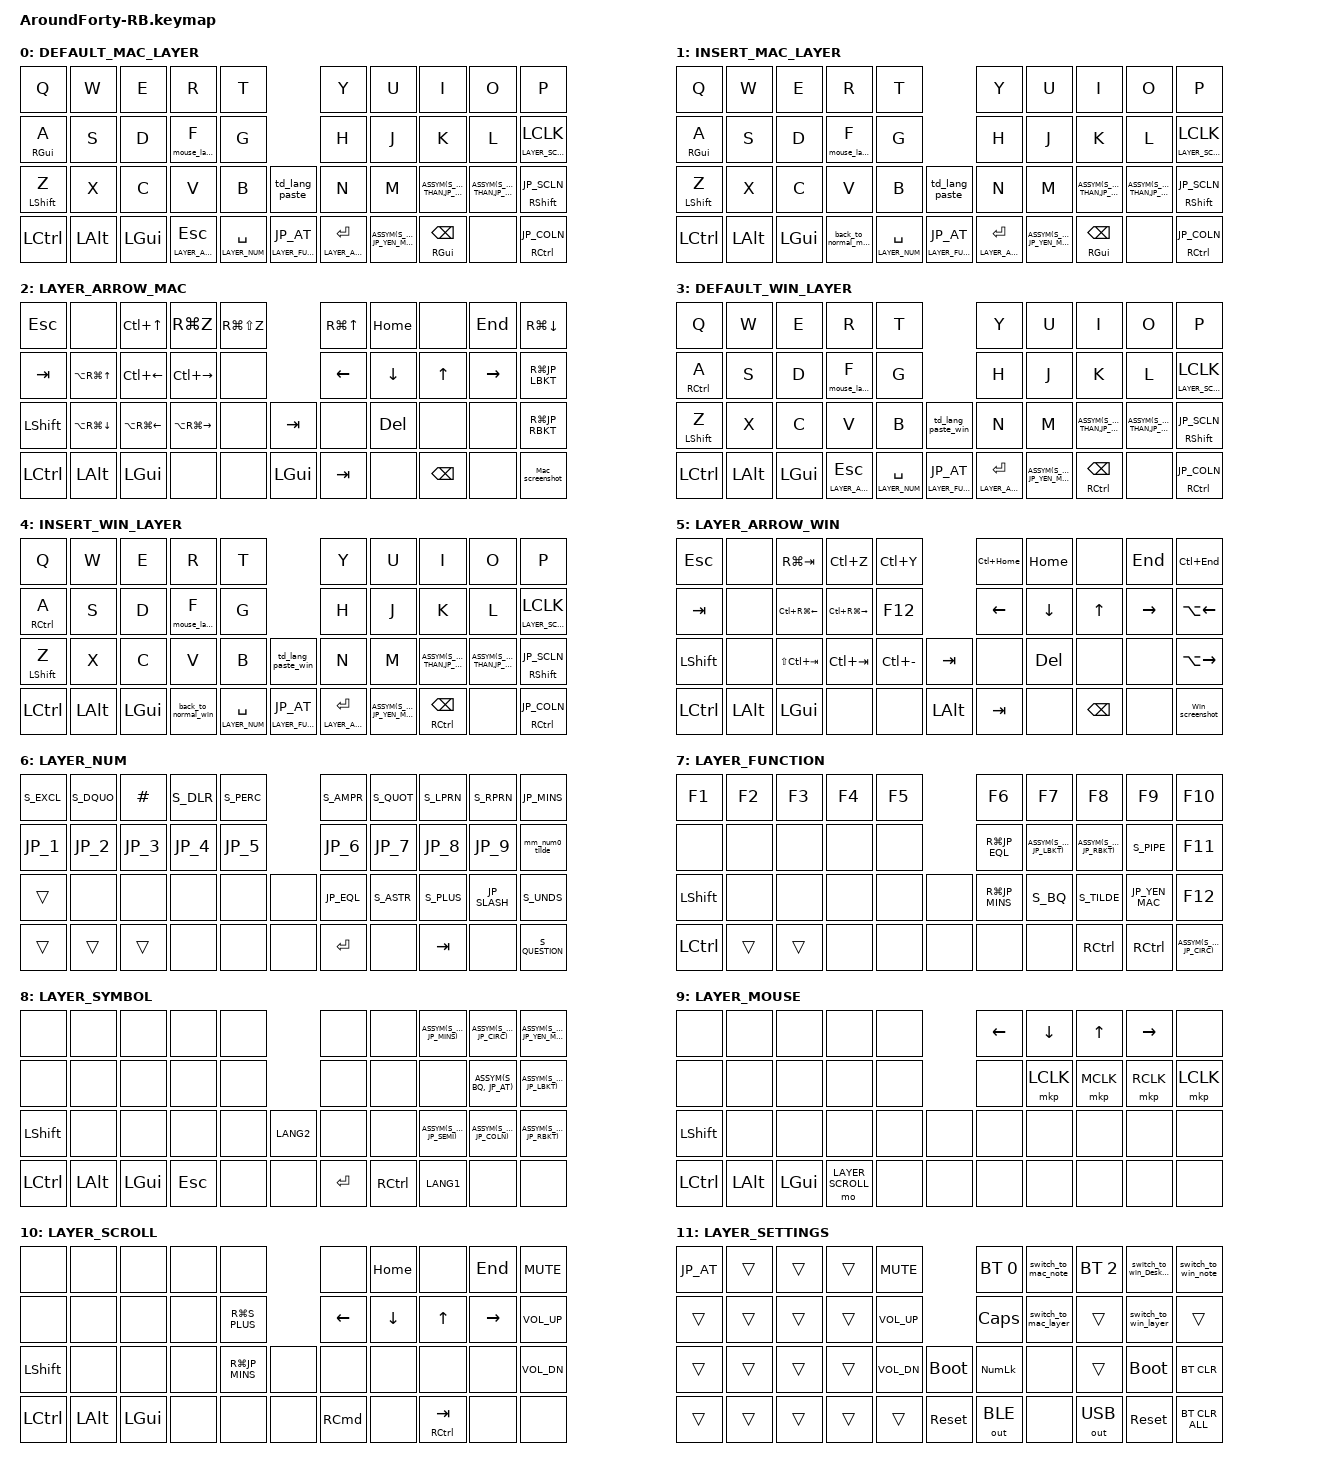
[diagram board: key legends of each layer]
#define ZMK_POINTING_DEFAULT_SCRL_VAL 120

#include <behaviors/rgbled_widget.dtsi>  // needed to use the behaviors
#include <behaviors.dtsi>
#include <dt-bindings/zmk/bt.h>
#include <dt-bindings/zmk/keys.h>
#include <dt-bindings/zmk/pointing.h>
#include <input/processors.dtsi>
#include <dt-bindings/zmk/outputs.h>

#include "code.h"

#define ASSYM(shifted, keycode) &auto_shift shifted keycode

// レイヤー定義
// デフォルトレイヤー (接続先ごと)
#define DEFAULT_MAC_LAYER      0  // Mac用デフォルトレイヤー
#define INSERT_MAC_LAYER       1  // Vim Insert(入力) Mac
#define LAYER_ARROW_MAC        2  // 矢印移動Macキーレイヤー

#define DEFAULT_WIN_LAYER      3  // Windows用デフォルトレイヤー
#define INSERT_WIN_LAYER       4  // Vim Insert(入力) Win
#define LAYER_ARROW_WIN        5  // 矢印移動Winキーレイヤー

// 機能レイヤー
#define LAYER_NUM 6            // 数字キーレイヤー
#define LAYER_FUNCTION 7       // ファンクションキーレイヤー
#define LAYER_SYMBOL 8         // 記号レイヤー
#define LAYER_MOUSE  9         // マウス操作レイヤー
#define LAYER_SCROLL 10        // スクロールレイヤー
#define LAYER_SETTINGS 11       // 設定レイヤー

//AML関連設定
//&zip_temp_layer {
//    excluded-positions = <
//        6 // U
//        7 // I
//        8 // O
//        //16 // J
//        //17 // K
//        //18 // L
//        //27 // M
//        //29 // .
//        31 // LEFT_CONTROL
//    >;
//};
//
////キー入力から一定時間はAMLを発動しない
//&zip_temp_layer {
//    require-prior-idle-ms = <500>;
//};
////マウスキーを押したらタイムアウトを延長する
//&mkp_input_listener {
//    input-processors = <&zip_temp_layer LAYER_MOUSE 10000>;
//};
////マウスキーを押すまでマウスレイヤーに留まる(マウスキーを押したらタイムアウトを延長すると同じ実装で、タイムアウト時間が違うだけ)
//&mkp_input_listener {
//    input-processors = <&zip_temp_layer LAYER_MOUSE 250>;
//};

&mt {
    flavor = "balanced";
    quick-tap-ms = <0>;
 
};

/ {
    combos {
        compatible = "zmk,combos"; 
        
        To_LayerSYMBOL {
            timeout-ms = <50>;
            bindings = <&togle_symbol>;  // SYMBOLレイヤーに移動

            key-positions = <11 12>;
            layers = <
                DEFAULT_MAC_LAYER           // Mac
                DEFAULT_WIN_LAYER           // Windows  
                LAYER_SYMBOL
            >;
        };

        To_LayerSETTING {
            bindings = <&mo LAYER_SETTINGS>;  // 設定レイヤーに移動
            //combo-term-ms = 30;
            key-positions = <34 35>;
        };

        // Mac: レイヤー戻しコンボ（ESCなし）
        combo_back_to_default_mac {
            timeout-ms = <800>;
            key-positions = <34 37>;
            bindings = <&back_to_default_mac>;
            layers = <INSERT_MAC_LAYER>, <DEFAULT_MAC_LAYER>;
        };

        // Win: レイヤー戻しコンボ（ESCなし）
        combo_back_to_default_win {
            timeout-ms = <800>;
            key-positions = <34 37>;
            bindings = <&back_to_default_win>;
            layers = <INSERT_WIN_LAYER>, <DEFAULT_WIN_LAYER>;
        };
 
        // f (13) + 右上1 (9) ➔ パイプ |
        combo_pipe { timeout-ms = <300>; key-positions = <13 9>; bindings = <&macro_pipe>; };
    
        // f (13) + 右上2 (19) ➔ 円マーク ¥
        combo_yen { timeout-ms = <300>; key-positions = <13 19>; bindings = <&macro_backslash>; };
    
        // f (13) + 右上3 (30) ➔ アンダーバー _
        combo_under { timeout-ms = <300>; key-positions = <13 30>; bindings = <&macro_under>; };

                /*
         * J + K：左クリック
         *
         * slow-releaseにより、
         * コンボ成立後にKを離しても、
         * Jを押している間は左クリックを維持する。
         */
        /* K + L：中クリック */
        combo_middle_click {
            timeout-ms = <40>;
            key-positions = <17 18>;
            bindings = <&mkp MCLK>;
            slow-release;
            //layers = <0>;
        };

        /* L + ;：右クリック */
        combo_right_click {
            timeout-ms = <40>;
            key-positions = <18 19>;
            bindings = <&mkp RCLK>;
            slow-release;
            //layers = <0>;
        };
    };

    macros {
        // F長押し時にMouse Layerを即時有効化する
        mouse_layer_eisu_hold: mouse_layer_eisu_hold {
            compatible = "zmk,behavior-macro";
            #binding-cells = <0>;
            wait-ms = <0>; tap-ms = <40>;
            bindings = <&macro_press &mo LAYER_MOUSE>, <&macro_pause_for_release>, <&macro_release &mo LAYER_MOUSE>;
        };

        // 指定したマウスボタンをクリックする
        mouse_button_eisu: mouse_button_eisu {
            compatible = "zmk,behavior-macro-one-param";
            #binding-cells = <1>;
            wait-ms = <30>; tap-ms = <40>;
            bindings = <&macro_param_1to1>, <&macro_tap &mkp MACRO_PLACEHOLDER>;
        };

        // パイプ | (Alt + 124)
        macro_pipe: macro_pipe {
            compatible = "zmk,behavior-macro";
            #binding-cells = <0>;
            wait-ms = <30>; tap-ms = <40>;
            bindings = <&macro_press &kp LALT>, <&macro_tap &kp KP_N1 &kp KP_N2 &kp KP_N4>, <&macro_release &kp LALT>;
        };
    
        // 円マーク ¥ (Alt + 165)
        macro_yen: macro_yen {
            compatible = "zmk,behavior-macro";
            #binding-cells = <0>;
            wait-ms = <30>; tap-ms = <40>;
            bindings = <&macro_press &kp LALT>, <&macro_tap &kp KP_N1 &kp KP_N6 &kp KP_N5>, <&macro_release &kp LALT>;
        };
    
        // アンダーバー _ (Alt + 95)
        macro_under: macro_under {
            compatible = "zmk,behavior-macro";
            #binding-cells = <0>;
            wait-ms = <30>; tap-ms = <40>;
            bindings = <&macro_press &kp LALT>, <&macro_tap &kp KP_N9 &kp KP_N5>, <&macro_release &kp LALT>;
        };
    
        // バックスラッシュ \ (Alt + 92)
        macro_backslash: macro_backslash {
            compatible = "zmk,behavior-macro";
            #binding-cells = <0>;
            wait-ms = <30>; tap-ms = <40>;
            bindings = <&macro_press &kp LALT>, <&macro_tap &kp KP_N9 &kp KP_N2>, <&macro_release &kp LALT>;
        };
 
        // Mac用: スロット1に合わせ、他を切断
        switch_to_mac_note: switch_to_mac_note {
            compatible = "zmk,behavior-macro";
            #binding-cells = <0>;
            bindings = <
                &macro_wait_time 50
                &bt BT_SEL 1
                &bt BT_DISC 0
                &bt BT_DISC 2
                &bt BT_DISC 3
                &bt BT_DISC 4
                &out OUT_BLE
            >;
        };

        // Win用: スロット3に合わせ、他を切断
        switch_to_win_Desktop: switch_to_win_Desktop {
            compatible = "zmk,behavior-macro";
            #binding-cells = <0>;
            bindings = <
                &macro_wait_time 50
                &bt BT_SEL 3
                &bt BT_DISC 0
                &bt BT_DISC 1
                &bt BT_DISC 2
                &bt BT_DISC 4
                &out OUT_BLE
            >;
        };

        // Win用: スロット4に合わせ、他を切断
        switch_to_win_note: switch_to_win_note {
            compatible = "zmk,behavior-macro";
            #binding-cells = <0>;
            bindings = <
                &macro_wait_time 50
                &bt BT_SEL 4
                &bt BT_DISC 0
                &bt BT_DISC 1
                &bt BT_DISC 2
                &bt BT_DISC 3
                &out OUT_BLE
            >;
        };

        // デフォルトレイヤーOFF
        reset_DefaultLayer: reset_DefaultLayer {
            compatible = "zmk,behavior-macro";
            #binding-cells = <0>;
            bindings = <

                // レイヤーをオフ
                &tog_off DEFAULT_MAC_LAYER 
                &tog_off DEFAULT_WIN_LAYER 
            >;
            label = "reset_DefaultLayer";
        };
        
        // Mac layer
        switch_to_mac_layer: switch_to_mac_layer {
            compatible = "zmk,behavior-macro";
            #binding-cells = <0>;
    
            bindings = <
                &reset_DefaultLayer
                &macro_wait_time 200

                // Bluetooth切断
                &bt BT_DISC 3
                &bt BT_DISC 4 

                &tog_on DEFAULT_MAC_LAYER
                &to DEFAULT_MAC_LAYER
                &out OUT_BLE
            >;
            label = "SWITCH_TO_MAC_LALYER";
        };

        // Win layer
        switch_to_win_layer: switch_to_win_layer {
            compatible = "zmk,behavior-macro";
            #binding-cells = <0>;
    
            bindings = <
                &reset_DefaultLayer
                &macro_wait_time 200

                // Bluetooth切断
                &bt BT_DISC 0
                &bt BT_DISC 1
                &bt BT_DISC 2

                &tog_on DEFAULT_WIN_LAYER
                &to DEFAULT_WIN_LAYER
                &out OUT_BLE
            >;
            label = "SWITCH_TO_WIN_LALYER";
        };

        to_layer_0: to_layer_0 {
            compatible = "zmk,behavior-macro-one-param";
            #binding-cells = <1>;
            bindings = <&to 0 &macro_param_1to1 &kp MACRO_PLACEHOLDER>;
            label = "TO_LAYER_0";
        };

        Mac_screenshot: Mac_screenshot {
            compatible = "zmk,behavior-macro";
            #binding-cells = <0>;
            bindings = <&kp RG(LS(N5))>;
            label = "MAC_SCREENSHOT";
        };

        Win_screenshot: Win_screenshot {
            compatible = "zmk,behavior-macro";
            #binding-cells = <0>;
            bindings = <&kp RG(LS(S))>;
            label = "WIN_SCREENSHOT";
        };

        to_default_layer: to_default_layer {
            compatible = "zmk,behavior-macro";
            #binding-cells = <0>;
            bindings = <&to DEFAULT_MAC_LAYER &to DEFAULT_WIN_LAYER>;
            label = "TO_DEFAULT_LAYER";
        };

        exit_num_lang2: exit_num_lang2 {
            compatible = "zmk,behavior-macro";
            #binding-cells = <0>;
            bindings = <
                &to_default_layer
                &kp LANG2
            >;
            label = "EXIT_NUM_LANG2";
        };

        exit_num_lang1: exit_num_lang1 {
            compatible = "zmk,behavior-macro";
            #binding-cells = <0>;
            bindings = <
                &to_default_layer
                &kp LANG1
            >;
            label = "EXIT_NUM_LANG1";
        };

        // 記号レイヤー移動
        togle_symbol: togle_symbol {
            label = "TOGGLE_SYMBOL";
            compatible = "zmk,behavior-macro";
            #binding-cells = <0>;
            bindings = 
                <&tog LAYER_SYMBOL>;  // 記号レイヤーに移動
        };

        // 入力レイヤー用：Esc→各OSのデフォルト（Vimノーマル）へ戻す（旧定義：残す）
        back_to_normal_mac: back_to_normal_mac {
            compatible = "zmk,behavior-macro";
            #binding-cells = <0>;
            bindings = <
                &kp ESCAPE          // Vimノーマルmodeへ
                &macro_wait_time 50
                &to DEFAULT_MAC_LAYER // Macデフォルトへ
            >;
        };

        back_to_normal_win: back_to_normal_win {
            compatible = "zmk,behavior-macro";
            #binding-cells = <0>;
            bindings = <
                &kp ESCAPE          // Vimノーマルmodeへ
                &macro_wait_time 50
                &to DEFAULT_WIN_LAYER // Winデフォルトへ
            >;
        };

        // ESCなしでレイヤー戻し（Mac用）- コンボ用
        back_to_default_mac: back_to_default_mac {
            compatible = "zmk,behavior-macro";
            #binding-cells = <0>;
            bindings = <
                &to DEFAULT_MAC_LAYER
            >;
        };

        // ESCなしでレイヤー戻し（Win用）- コンボ用
        back_to_default_win: back_to_default_win {
            compatible = "zmk,behavior-macro";
            #binding-cells = <0>;
            bindings = <
                &to DEFAULT_WIN_LAYER
            >;
        };

        /* --- ESCとLang2を送る --- */
        esc_lang: esc_lang {
            compatible = "zmk,behavior-macro";
            #binding-cells = <0>;
            bindings = <
                &kp ESCAPE                // Escape
                &kp LANG2                 // 半角入力へ
            >;
        };

        // Altを2回送るマクロ
        win_clip_altalt: win_clip_altalt {
            compatible = "zmk,behavior-macro";
            #binding-cells = <0>;
            bindings = <
                &kp LALT            // 1回目
                &macro_wait_time 80 // 適宜調整
                &kp LALT            // 2回目
            >;
        };
    };

    behaviors {
        lt_to_layer_0: lt_to_layer_0 {
            compatible = "zmk,behavior-hold-tap";
            label = "LAYER_TAP_TO_0";
            bindings = <&mo>, <&to_layer_0>;

            #binding-cells = <2>;
            tapping-term-ms = <200>;
        };

        scroll_up_down: behavior_sensor_rotate_mouse_wheel_up_down {
            compatible = "zmk,behavior-sensor-rotate";
            #sensor-binding-cells = <0>;
            bindings = <&msc SCRL_UP>, <&msc SCRL_DOWN>;

            tap-ms = <20>;
        };

        //AutoShift
        auto_shift: auto_shift {
            compatible = "zmk,behavior-hold-tap";
            #binding-cells = <2>;
            tapping_term_ms = <180>;
            quick_tap_ms = <200>;
            flavor = "tap-preferred";
            require-prior-idle-ms = <120>;
            bindings = <&kp>, <&kp>;
        };

        //移動レイヤートグル
        lt_arrow_tog: lt_arrow_tog {
            compatible = "zmk,behavior-hold-tap";
            label = "LAYER_ARROW_TOG";
            #binding-cells = <2>;
            tapping-term-ms = <200>;
            quick-tap-ms = <0>;
            flavor = "tap-preferred";
            bindings = <&tog>, <&kp>;
        };

        //矢印レイヤーに移動がたまに失敗するため
        lt_arrow: lt_arrow {
            compatible = "zmk,behavior-hold-tap";
            label = "LAYER_TAP_ARROW";
            #binding-cells = <2>;
            tapping-term-ms = <250>;
            quick-tap-ms = <200>;
            flavor = "hold-preferred";
            bindings = <&mo>, <&kp>;
        };

        lt_layer_tap_preferred: lt_layer_tap_preferred {
            compatible = "zmk,behavior-hold-tap";
            label = "LAYER_TAP_TAP_PREF";
            #binding-cells = <2>;
            tapping-term-ms = <200>;
            flavor = "tap-preferred";
            bindings = <&mo>, <&kp>;
        };

        /*
         * 単押しではマウスボタン、長押し中は指定したレイヤーを有効にする。
         *
         * 使い方:
         *   &lt_mkp LAYER_SCROLL LCLK
         *   1つ目: 長押し中に有効にするレイヤー
         *   2つ目: 単押しで送るマウスボタン
         */
        lt_mkp: lt_mkp {
            compatible = "zmk,behavior-hold-tap";
            label = "LAYER_TAP_MOUSE_BUTTON";
            #binding-cells = <2>;
            tapping-term-ms = <200>;
            quick-tap-ms = <0>;
            flavor = "hold-preferred";
            bindings = <&mo>, <&mouse_button_eisu>;
        };

        // F: タップはF、長押しは英数化してMouse Layerを有効にする
        lt_mouse_eisu: lt_mouse_eisu {
            compatible = "zmk,behavior-hold-tap";
            label = "LAYER_TAP_MOUSE_EISU";
            #binding-cells = <2>;
            flavor = "tap-preferred";
            tapping-term-ms = <200>;
            bindings = <&mouse_layer_eisu_hold>, <&kp>;
        };

        /* 注意:
        *  - bindings の tap 側を &kp から &td_* に差し替えるため、
        *    keymap から渡す引数は「レイヤー」だけになる
        *  - そのため #binding-cells は <1> にする
        */
        // Arrow用: hold=押している間レイヤー / tap=（1回LANG2,2回ESC）
        lt_arrow_td: lt_arrow_td {
            compatible = "zmk,behavior-hold-tap";           // #hold-tap
            label = "LAYER_TAP_ARROW_TD";                   // #識別ラベル
            #binding-cells = <2>;                           // #引数はレイヤー1つだけ
            tapping-term-ms = <250>;                        // #元の lt_arrow と同じ
            quick-tap-ms = <200>;                           // #元の lt_arrow と同じ
            flavor = "hold-preferred";                      // #元の lt_arrow と同じ
            bindings = <&mo>, <&td_lang2_esc>;              // #hold=&mo, #tap=&td_lang2_esc
        };

        // Function用: hold=押している間レイヤー / tap=&kp
        lt_layer_tap_preferred_td: lt_layer_tap_preferred_td {
            compatible = "zmk,behavior-hold-tap";           // #hold-tap
            label = "LAYER_TAP_TAP_PREF_TD";                // #識別ラベル
            #binding-cells = <2>;                           // #引数はレイヤー1つだけ
            tapping-term-ms = <200>;                        // #元の lt_layer_tap_preferred と同じ
            flavor = "tap-preferred";                       // #元の lt_layer_tap_preferred と同じ
            bindings = <&mo>, <&kp>;                        // #hold=&mo, #tap=&kp
        };
        
        tog_on: toggle_layer_on_only {
            compatible = "zmk,behavior-toggle-layer";
            #binding-cells = <1>;
            display-name = "Toggle Layer On";
            toggle-mode = "on";
        };

        tog_off: toggle_layer_off_only {
            compatible = "zmk,behavior-toggle-layer";
            #binding-cells = <1>;
            display-name = "Toggle Layer Off";
            toggle-mode = "off";
        };

        ht_kp_tap: ht_kp_tap {
            compatible = "zmk,behavior-hold-tap";
            label = "HT_KP_TAP_PREF";
            #binding-cells = <2>;
            tapping-term-ms = <200>;      // 好みで共通値
            quick-tap-ms = <200>;         // 要らなければ削除
            flavor = "tap-preferred";
            bindings = <&kp>, <&kp>;
        };

        ht_kp_hold: ht_kp_hold {
            compatible = "zmk,behavior-hold-tap";
            label = "HT_KP_HOLD_PREF";
            #binding-cells = <2>;
            tapping-term-ms = <200>;
            quick-tap-ms = <200>;
            flavor = "hold-preferred";
            bindings = <&kp>, <&kp>;
        };

        td_lang_paste: td_lang_paste {
            compatible = "zmk,behavior-tap-dance";
            label = "TD_LANG_PASTE";
            #binding-cells = <0>;
            tapping-term-ms = <350>;
            bindings = <&kp LANG2>, <&kp LANG1>, <&kp LC(LA(V))>;
        };

        // tap dance の3タップ目に差し込む
        td_lang_paste_win: td_lang_paste_win {
            compatible = "zmk,behavior-tap-dance";
            #binding-cells = <0>;
            label = "TD_LANG_PASTE_WIN";
            tapping-term-ms = <350>;
            bindings = <
                &kp INT_MUHENKAN  // 英数 (Meltype: 無変換で英数)
                &kp INT_HENKAN    // 日本語 (Meltype: 変換で日本語)
                &win_clip_altalt           
            >;
        };

        // ================================
        // ① td_lang2_esc → td_lang1_esc 置換
        //    Insertレイヤ用：1tap=日本語 / 2tap=ESC
        // ================================ */
        td_lang1_esc: td_lang1_esc {
            compatible = "zmk,behavior-tap-dance";     // 日本語寄せ＋Esc 用 tap-dance
            label = "TD_LANG1_ESC";                    // 任意ラベル（識別用）
            #binding-cells = <0>;
            tapping-term-ms = <350>;                   // 既存 td_lang2_esc と同等想定
            bindings = <&kp LANG1>, <&kp ESCAPE>;      // 1tap=LANG1 / 2tap=ESC
        };

        // 1回: LANG2 / 2回: ESCAPE（holdは lt_arrow 側で LAYER_ARROW_MAC のまま）
        td_lang2_esc: td_lang2_esc {
            compatible = "zmk,behavior-tap-dance";          // tap-dance behavior
            label = "TD_LANG2_ESC";                         // 任意ラベル（識別用）
            #binding-cells = <0>;                           // 引数なしで参照する
            tapping-term-ms = <350>;                        // 2回目受付時間（必要なら調整）
            bindings = <&kp LANG2>, <&kp ESCAPE>;           // 1回目 / 2回目
        };


        // 旧定義：残す（入力レイヤー用：1tap=LANG2 / 2tap=ESC / 3tap=back_to_normal_*）
        td_lang2_back_mac: td_lang2_back_mac {
            compatible = "zmk,behavior-tap-dance";
            #binding-cells = <0>;
            tapping-term-ms = <350>;
            bindings = <
                &kp LANG2
                &kp ESCAPE
                &back_to_normal_mac
            >;
        };

        td_lang2_back_win: td_lang2_back_win {
            compatible = "zmk,behavior-tap-dance";
            #binding-cells = <0>;
            tapping-term-ms = <350>;
            bindings = <
                &kp LANG2
                &kp ESCAPE
                &back_to_normal_win
            >;
        };

//InputLayerを日本語専用入力に変更のため、コメントアウト
//        // デフォルトレイヤ用：iキー 1tap=i / 2tap=入力レイヤへ（iは送らない）
//        td_i_insert_mac: td_i_insert_mac {
//            compatible = "zmk,behavior-tap-dance";
//            #binding-cells = <0>;
//            tapping-term-ms = <230>;
//            bindings = <&kp I>, <&to INSERT_MAC_LAYER>;
//        };
//
//        td_i_insert_win: td_i_insert_win {
//            compatible = "zmk,behavior-tap-dance";
//            #binding-cells = <0>;
//            tapping-term-ms = <230>;
//            bindings = <&kp I>, <&to INSERT_WIN_LAYER>;
//        };

        /* --- Mac 用：日本語化して Insert へ --- */
        enter_insert_jp_mac: enter_insert_jp_mac {
            compatible = "zmk,behavior-macro";
            #binding-cells = <0>;
            bindings = <
                &kp LANG1                 // 日本語入力へ
                &macro_wait_time 100      // 取りこぼし軽減（既存運用に合わせて調整可）
                &to INSERT_MAC_LAYER      // Insert(Mac) レイヤへ
            >;
        };
        
        td_i_insert_mac: td_i_insert_mac {
            compatible = "zmk,behavior-tap-dance";
            #binding-cells = <0>;
            tapping-term-ms = <230>;      // 既存値維持
            bindings = <&kp I>, <&enter_insert_jp_mac>;
        };
        
        
        /* --- Windows 用：日本語化して Insert へ --- */
        enter_insert_jp_win: enter_insert_jp_win {
            compatible = "zmk,behavior-macro";
            #binding-cells = <0>;
            bindings = <
                &kp LANG1                 // 日本語入力へ
                &macro_wait_time 100      // 取りこぼし軽減（既存運用に合わせて調整可） 
                &to INSERT_WIN_LAYER      // Insert(Win) レイヤへ
            >;
        };
        
        td_i_insert_win: td_i_insert_win {
            compatible = "zmk,behavior-tap-dance";
            #binding-cells = <0>;
            tapping-term-ms = <230>;
            bindings = <&kp I>, <&enter_insert_jp_win>;
        };




        // 1回: LANG1 / 2回: JP_AT（holdは lt_layer_tap_preferred 側で LAYER_FUNCTION のまま）
        td_lang1_at: td_lang1_at {
            compatible = "zmk,behavior-tap-dance";          // tap-dance behavior
            label = "TD_LANG1_AT";                          // 任意ラベル（識別用）
            #binding-cells = <0>;                           // 引数なしで参照する
            tapping-term-ms = <350>;                        // 2回目受付時間（必要なら調整）
            bindings = <&kp LANG1>, <&kp JP_AT>;            // 1回目 / 2回目（JP_ATはあなたのJIS用コード前提）
        };

        mm_num0_tilde: mm_num0_tilde {
            compatible = "zmk,behavior-mod-morph";
            #binding-cells = <0>;
            mods = <(MOD_LSFT | MOD_RSFT)>;
            bindings = <&kp JP_0 &kp JP_CIRC>;
        };

        mm_BS_DEL: mm_BS_DEL {
            compatible = "zmk,behavior-mod-morph";
            #binding-cells = <0>;
            mods = <(MOD_LSFT | MOD_RSFT)>;
            bindings = <&kp BACKSPACE &kp DELETE>;
        };
        /*
         * タップ：左クリック
         * ホールド：右Ctrl
         *
         * 使用時：
         * &kp_mclk RCTRL LCLK
         */
        kp_mclk: kp_mclk {
            compatible = "zmk,behavior-hold-tap";
            #binding-cells = <2>;

            flavor = "hold-preferred";
            tapping-term-ms = <200>;

            bindings = <&kp>, <&mkp>;
        };
    };

//////// 重要 ////////
//３段目の右側の一番左の設定は４段目の右の左から２番めに設定する必要あり
//また４段目の右側の一番左に２番目に押すキーを設定して、３番目に１番目のキーを設定するようにしないといけない
//例として右側の設定
//タブ、Enterという設定の場合、Enter、３段目の一番左のキー、タブ
//という流れでキー設定をする
//////// 重要 ////////

    keymap {
        compatible = "zmk,keymap";
        DEFAULT_MAC_LAYER  {
            bindings = <
&kp Q             &kp W         &kp E         &kp R                                &kp T                                                                                     &kp Y                            &kp U                      &kp I                        &kp O                         &kp P
&mt RIGHT_GUI A   &kp S         &kp D         &lt_mouse_eisu 0 F                   &kp G                                                                                     &kp H                            &kp J                      &kp K                        &kp L                         &lt_mkp LAYER_SCROLL LCLK
&mt LEFT_SHIFT Z  &kp X         &kp C         &kp V                                &kp B                                     &td_lang_paste                                  &kp N                            &kp M                      ASSYM(S_LESS_THAN,JP_COMMA)  ASSYM(S_GREATER_THAN,JP_DOT)  &mt RIGHT_SHIFT JP_SCLN
&kp LCTRL         &kp LEFT_ALT  &kp LEFT_GUI  &lt_arrow LAYER_ARROW_MAC ESCAPE     &lt_layer_tap_preferred LAYER_NUM SPACE   &lt_layer_tap_preferred LAYER_FUNCTION JP_AT    &lt_arrow LAYER_ARROW_MAC ENTER        ASSYM(S_PIPE, JP_YEN_MAC)  &mt RIGHT_GUI BACKSPACE        &none                 &mt RCTRL JP_COLN
            >;
        };

        INSERT_MAC_LAYER {
            bindings = <      
&kp Q             &kp W         &kp E         &kp R                                &kp T                                                                                     &kp Y                            &kp U                      &kp I                        &kp O                         &kp P
&mt RIGHT_GUI A   &kp S         &kp D         &lt_mouse_eisu 0 F                   &kp G                                                                                     &kp H                            &kp J                      &kp K                        &kp L                         &lt_mkp LAYER_SCROLL LCLK
&mt LEFT_SHIFT Z  &kp X         &kp C         &kp V                                &kp B                                     &td_lang_paste                                  &kp N                            &kp M                      ASSYM(S_LESS_THAN,JP_COMMA)  ASSYM(S_GREATER_THAN,JP_DOT)  &mt RIGHT_SHIFT JP_SCLN
&kp LCTRL         &kp LEFT_ALT  &kp LEFT_GUI  &back_to_normal_mac                  &lt_layer_tap_preferred LAYER_NUM SPACE   &lt_layer_tap_preferred_td LAYER_FUNCTION JP_AT           &lt_arrow LAYER_ARROW_MAC ENTER  ASSYM(S_PIPE, JP_YEN_MAC)  &mt RIGHT_GUI BACKSPACE        &none             &mt RCTRL JP_COLN
            >;
        };

        LAYER_ARROW_MAC {
            bindings = <
&kp ESCAPE        &none                  &kp LC(UP_ARROW)        &kp RG(Z)                &kp RG(LS(Z))                             &kp RG(UP_ARROW)                   &kp HOME                &none            &kp END      &kp RG(DOWN_ARROW)
&kp TAB           &kp LA(RG(UP_ARROW))   &kp LC(LEFT_ARROW)      &kp LC(RIGHT_ARROW)      &none                                     &kp LEFT                           &kp DOWN_ARROW          &kp UP_ARROW     &kp RIGHT_ARROW          &kp RG(JP_LBKT)
&kp LEFT_SHIFT    &kp LA(RG(DOWN_ARROW)) &kp LA(RG(LEFT_ARROW))  &kp LA(RG(RIGHT_ARROW))  &none           &kp TAB                   &none                              &kp DELETE              &none            &none                    &kp RG(JP_RBKT)
&kp LCTRL         &kp LEFT_ALT           &kp LEFT_GUI            &none                    &none           &kp LEFT_GUI              &kp TAB                            &none                   &kp BACKSPACE    &none                    &Mac_screenshot
            >;
        };


//Windows用レイヤー
    DEFAULT_WIN_LAYER {
            bindings = <
&kp Q             &kp W         &kp E         &kp R                  &kp T                                                           &kp Y        &kp U           &kp I                     &kp O       &kp P
&mt RCTRL A       &kp S         &kp D         &lt_mouse_eisu 0 F     &kp G                                                           &kp H        &kp J           &kp K          &kp L       &lt_mkp LAYER_SCROLL LCLK
&mt LEFT_SHIFT Z  &kp X         &kp C         &kp V                  &kp B         &td_lang_paste_win                                &kp N        &kp M           ASSYM(S_LESS_THAN,JP_COMMA)  ASSYM(S_GREATER_THAN,JP_DOT)  &mt RIGHT_SHIFT JP_SCLN
&kp LCTRL         &kp LEFT_ALT  &kp LEFT_GUI  &lt_arrow LAYER_ARROW_WIN ESCAPE     &lt_layer_tap_preferred LAYER_NUM SPACE   &lt_layer_tap_preferred LAYER_FUNCTION JP_AT    &lt_arrow LAYER_ARROW_WIN ENTER  ASSYM(S_PIPE, JP_YEN_MAC)  &mt RCTRL BACKSPACE        &none                         &mt RCTRL JP_COLN
            >;
    };

        INSERT_WIN_LAYER {
            bindings = <
&kp Q             &kp W         &kp E         &kp R                  &kp T                                                           &kp Y        &kp U        &kp I                      &kp O       &kp P
&mt RCTRL A       &kp S         &kp D         &lt_mouse_eisu 0 F     &kp G                                                           &kp H        &kp J        &kp K          &kp L       &lt_mkp LAYER_SCROLL LCLK
&mt LEFT_SHIFT Z  &kp X         &kp C         &kp V                  &kp B         &td_lang_paste_win                                &kp N        &kp M        ASSYM(S_LESS_THAN,JP_COMMA)  ASSYM(S_GREATER_THAN,JP_DOT)  &mt RIGHT_SHIFT JP_SCLN
&kp LCTRL         &kp LEFT_ALT  &kp LEFT_GUI  &back_to_normal_win    &lt_layer_tap_preferred LAYER_NUM SPACE   &lt_layer_tap_preferred_td LAYER_FUNCTION JP_AT           &lt_arrow LAYER_ARROW_WIN ENTER  ASSYM(S_PIPE, JP_YEN_MAC)  &mt RCTRL BACKSPACE        &none                         &mt RCTRL JP_COLN
            >;
        };

        LAYER_ARROW_WIN {
            bindings = <
&kp ESCAPE        &none         &kp RG(TAB)                &kp LC(Z)           &kp LC(Y)                                           &kp LC(HOME)                         &kp HOME        &none                &kp END       &kp LC(END)
&kp TAB           &none         &kp LC(RG(LEFT))           &kp LC(RG(RIGHT))   &kp F12                                             &kp LEFT                             &kp DOWN_ARROW  &kp UP_ARROW         &kp RIGHT_ARROW  &kp LA(LEFT)
&kp LEFT_SHIFT    &none         &kp LS(LC(TAB))            &kp LC(TAB)         &kp LC(MINUS)   &kp TAB                             &none                                &kp DELETE                           &none           &none         &kp LA(RIGHT)
&kp LCTRL         &kp LEFT_ALT  &kp LEFT_GUI               &none               &none           &kp LEFT_ALT                        &kp TAB                              &none           &kp BACKSPACE        &none           &Win_screenshot
            >;
        };

        LAYER_NUM {
            bindings = <
&kp S_EXCL          &kp S_DQUO  &kp HASH     &kp S_DLR    &kp S_PERC                     &kp S_AMPR       &kp S_QUOT     &kp S_LPRN      &kp S_RPRN       &kp JP_MINS
&kp JP_1            &kp JP_2    &kp JP_3     &kp JP_4     &kp JP_5                       &kp JP_6         &kp JP_7       &kp JP_8        &kp JP_9         &mm_num0_tilde
&trans              &none       &none        &none        &none        &none             &kp JP_EQL       &kp S_ASTR     &kp S_PLUS      &kp JP_SLASH     &kp S_UNDS
&trans              &trans      &trans       &none        &none        &none             &kp ENTER        &none          &kp TAB         &none            &kp S_QUESTION
            >;
        };

        LAYER_FUNCTION {
            bindings = <
&kp F1                  &kp F2  &kp F3     &kp F4 &kp F5                                    &kp F6            &kp F7                    &kp F8                  &kp F9           &kp F10
&none                   &none   &none      &none  &none                                     &kp RG(JP_EQL)    ASSYM(S_LCBR, JP_LBKT)    ASSYM(S_RCBR, JP_RBKT)  &kp S_PIPE       &kp F11
&kp LEFT_SHIFT          &none   &none      &none  &none           &none                     &kp RG(JP_MINS)   &kp S_BQ                  &kp S_TILDE             &kp JP_YEN_MAC   &kp F12
&kp LEFT_CONTROL        &trans  &trans     &none  &none           &none                     &none             &none                     &kp RCTRL               &kp RCTRL        ASSYM(S_TILDE, JP_CIRC)
            >;
        };

        LAYER_SYMBOL {
            bindings = <
&none  &none  &none  &none  &none                                          &none       &none   ASSYM(S_EQL, JP_MINS)    ASSYM(S_TILDE, JP_CIRC)   ASSYM(S_PIPE, JP_YEN_MAC)
&none  &none  &none  &none  &none                                          &none       &none   &none                    ASSYM(S_BQ, JP_AT)        ASSYM(S_LCBR, JP_LBKT)
&kp LEFT_SHIFT  &none  &none  &none  &none  &kp LANG2                      &none       &none   ASSYM(S_PLUS, JP_SEMI)   ASSYM(S_ASTR, JP_COLN)    ASSYM(S_RCBR, JP_RBKT)
&kp LEFT_CONTROL     &kp LEFT_ALT  &kp LEFT_GUI  &kp ESCAPE  &none  &none       &kp ENTER   &kp RCTRL   &kp LANG1  &none                          &none
            >;
        };

//例として右側の設定
//タブ、Enterという設定の場合、Enter、３段目の一番左のキー、タブ
//という流れでキー設定をする

        LAYER_MOUSE {
            bindings = <
&none           &none         &none         &none            &none              &kp LEFT    &kp DOWN   &kp UP     &kp RIGHT  &none
&none           &none         &none         &none            &none              &none       &mkp LCLK  &mkp MCLK  &mkp RCLK  &mkp LCLK
&kp LEFT_SHIFT  &none         &none         &none            &none       &none  &none       &none      &none      &none      &none
&kp LCTRL       &kp LEFT_ALT  &kp LEFT_GUI  &mo LAYER_SCROLL &none       &none  &none       &none      &none      &none      &none
            >;
        };

        LAYER_SCROLL {
            bindings = <
&none           &none         &none         &none            &none                          &none              &kp HOME      &none            &kp END      &kp C_MUTE
&none           &none         &none         &none            &kp RG(S_PLUS)                 &kp LEFT           &kp DOWN      &kp UP           &kp RIGHT    &kp C_VOL_UP
&kp LEFT_SHIFT  &none         &none         &none            &kp RG(JP_MINS)         &none  &none              &none         &none            &none        &kp C_VOL_DN
&kp LCTRL       &kp LEFT_ALT  &kp LEFT_GUI  &none            &none                   &none  &kp RIGHT_COMMAND  &none         &mt RCTRL TAB    &none        &none
            >;
        };

        LAYER_SETTINGS {
            bindings = <
&kp JP_AT  &trans  &trans  &trans  &kp C_MUTE                 &bt BT_SEL 0    &switch_to_mac_note    &bt BT_SEL 2    &switch_to_win_Desktop  &switch_to_win_note
&trans     &trans  &trans  &trans  &kp C_VOL_UP               &kp CAPS        &switch_to_mac_layer   &trans          &switch_to_win_layer    &trans
&trans     &trans  &trans  &trans  &kp C_VOL_DN  &bootloader  &kp KP_NUMLOCK  &none                  &trans          &bootloader             &bt BT_CLR
&trans     &trans  &trans  &trans  &trans        &sys_reset   &out OUT_BLE    &none                  &out OUT_USB    &sys_reset              &bt BT_CLR_ALL
            >;
        };
    };
};
